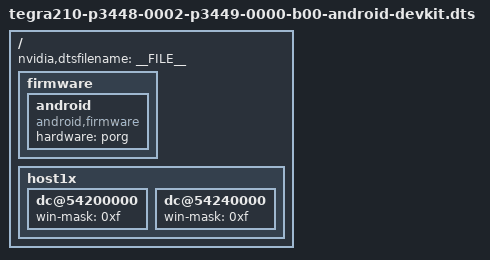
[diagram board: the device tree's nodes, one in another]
#include "tegra210-p3448-0002-p3449-0000-b00.dts"

/ {
	nvidia,dtsfilename = __FILE__;

	firmware {
		android {
			compatible = "android,firmware";
			hardware = "porg";
		};
	};

	host1x {
		dc@54200000 {
			win-mask = <0xf>;
		};

		dc@54240000 {
			win-mask = <0xf>;
		};
	};
};
